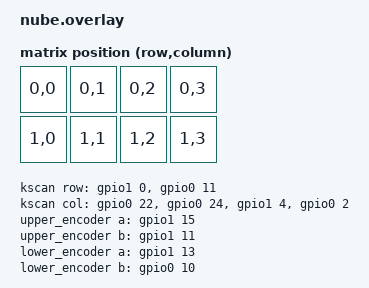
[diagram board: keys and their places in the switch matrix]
// This file was generated from a template. Edit it to match your keyboard.
// See https://zmk.dev/docs/development/hardware-integration/new-shield for more
// instructions.

#include <dt-bindings/zmk/matrix_transform.h>

#include "nube-layouts.dtsi"

/ {
    chosen {
        zmk,physical-layout = &default_layout;
    };

    kscan: kscan {
        // If the hardware does not use a switch matrix, change this to the
        // appropriate driver and update the properties below to match.
        // See https://zmk.dev/docs/config/kscan for supported key scan drivers.
        compatible = "zmk,kscan-gpio-matrix";
        // Set this to "col2row" or "row2col" to match the hardware. If using
        // "row2col", change the col-gpios to (GPIO_ACTIVE_HIGH | GPIO_PULL_DOWN)
        // and the row-gpios to GPIO_ACTIVE_HIGH.
        diode-direction = "col2row";
        wakeup-source;

        // Replace these comments with the GPIO pins in the matrix.
        // See https://zmk.dev/docs/development/hardware-integration/new-shield#shield-overlays
        col-gpios
          = <&gpio0 22 GPIO_ACTIVE_HIGH> //A
          , <&gpio0 24 GPIO_ACTIVE_HIGH> //B
          , <&gpio1  4 GPIO_ACTIVE_HIGH> //C
          , <&gpio0  2 GPIO_ACTIVE_HIGH> //D
          ;

        row-gpios
            = <&gpio1  0  (GPIO_ACTIVE_HIGH | GPIO_PULL_DOWN)> //1
            , <&gpio0 11  (GPIO_ACTIVE_HIGH | GPIO_PULL_DOWN)> //2
            ;
    };

    default_transform: default_transform {
        // See https://zmk.dev/docs/development/hardware-integration/new-shield#matrix-transform
        // for how to configure this
        compatible = "zmk,matrix-transform";
        columns = <4>;
        rows = <2>;

        map = <
            RC(0, 0) RC(0, 1) RC(0, 2) RC(0, 3)
            RC(1, 0) RC(1, 1) RC(1, 2) RC(1, 3)
        >;
    };

    upper_encoder: encoder_upper {
    compatible = "alps,ec11";
    a-gpios = <&gpio1 15 (GPIO_ACTIVE_HIGH | GPIO_PULL_UP)>;
    b-gpios = <&gpio1 11 (GPIO_ACTIVE_HIGH | GPIO_PULL_UP)>;
    steps = <80>;
    status = "okay";
  };

  lower_encoder: encoder_lower {
    compatible = "alps,ec11";
    a-gpios = <&gpio1 13 (GPIO_ACTIVE_HIGH | GPIO_PULL_UP)>;
    b-gpios = <&gpio0 10 (GPIO_ACTIVE_HIGH | GPIO_PULL_UP)>;
    steps = <80>;
    status = "okay";
  };

  sensors: sensors {
    compatible = "zmk,keymap-sensors";
    sensors = <&upper_encoder &lower_encoder>;
    triggers-per-rotation = <20>;
  };
};
